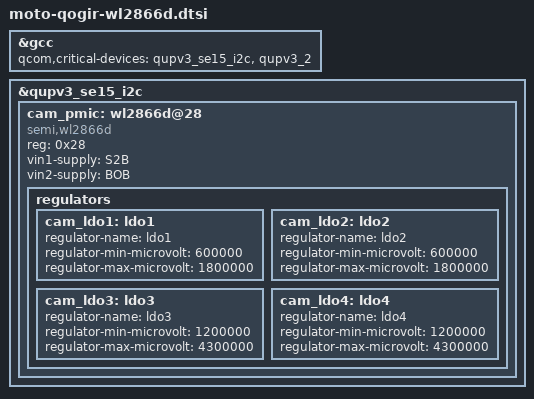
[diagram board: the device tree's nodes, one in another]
/*
 * Each QUP device that's a parent to PMIC must be listed as a critical device
 * to GCC.
 */

&gcc {
	qcom,critical-devices = <&qupv3_se15_i2c>, <&qupv3_2>;
};

&qupv3_se15_i2c {
	status = "ok";
	//aw37004 and wl2866d use same driver code
	cam_pmic: wl2866d@28 {
		compatible = "semi,wl2866d";
		reg = <0x28>;

		vin1-supply = <&S2B>;
		vin2-supply = <&BOB>;

		regulators {
			cam_ldo1: ldo1 {
				regulator-name = "ldo1";
				regulator-min-microvolt = <600000>;
				regulator-max-microvolt = <1800000>;
			};

			cam_ldo2: ldo2 {
				regulator-name = "ldo2";
				regulator-min-microvolt = <600000>;
				regulator-max-microvolt = <1800000>;
			};

			cam_ldo3: ldo3 {
				regulator-name = "ldo3";
				regulator-min-microvolt = <1200000>;
				regulator-max-microvolt = <4300000>;
			};

			cam_ldo4: ldo4 {
				regulator-name = "ldo4";
				regulator-min-microvolt = <1200000>;
				regulator-max-microvolt = <4300000>;
			};
		};
	};
};
